# SAMA7G54D4G device description
Architecture: CORTEX-A7; Family: SAMA; Series: SAMA7G
Registers are 32-bit, read-write, reset 0x0 unless marked. A register's access mark holds for its fields unless they carry their own. Offsets are from the block's base; [hi:lo] are bit positions; {n}, {i} and the like mark numbered series; 'fields as' and 'values as' point back to an identical list.

## GPBR — General Purpose Backup Registers
Instances: GPBR 0xE001D060
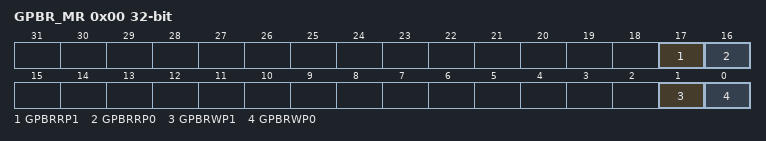
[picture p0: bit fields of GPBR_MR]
0x00 GPBR_MR — GPBR Mode Register
  [17] GPBRRP1 — GPBRx Read Protection
    0=The content of the corresponding GPBR register (32-bit part-select) can be read; 1=The corresponding GPBR register (32-bit part-select) always returns zero when read
  [16] GPBRRP0 — GPBRx Read Protection
    values as GPBRRP1
  [1] GPBRWP1 — GPBRx Write Protection
    0=The corresponding GPBR register (32-bit part-select) can be written; 1=The corresponding GPBR register (32-bit part-select) is write-protected
  [0] GPBRWP0 — GPBRx Write Protection
    values as GPBRWP1
0x04 GPBR_FCLR (atomic clear) — GPBR Full Clear Register
  [0] FCLR — Full Clear Enable
    0=SYS_GPBR0 to SYS_GPBR1 are immediately cleared in case of fast wakeup pin tamper event; 1=All SYS_GPBRx are immediately cleared in case of fast wakeup pin tamper event
{0x8+4i} SYS_GPBR[{i}] (i=0..1) — General Purpose Backup Register x
  [31:0] GPBR_VALUE — Value of SYS_GPBRx

## MCAN_RXBE — Rx Buffer Element
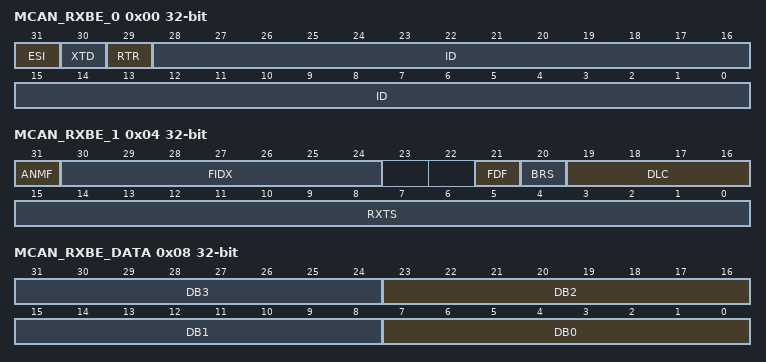
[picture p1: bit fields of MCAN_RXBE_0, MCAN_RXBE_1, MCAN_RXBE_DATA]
0x00 MCAN_RXBE_0 reset not defined — Rx Buffer Element 0
  [31] ESI — Error State Indicator
  [30] XTD — Extended Identifier
  [29] RTR — Remote Transmission Request
  [28:0] ID — Identifier
0x04 MCAN_RXBE_1 reset not defined — Rx Buffer Element 1
  [31] ANMF — Accepted Non-matching Frame
  [30:24] FIDX — Filter Index
  [21] FDF — FD Format
  [20] BRS — Bit Rate Switch
  [19:16] DLC — Data Length Code
  [15:0] RXTS — Rx Timestamp
0x08 MCAN_RXBE_DATA reset not defined — Rx Buffer Element Data
  [8n+7:8n] DB{n} (n=0..3) — Data Byte {n}

## MCAN_RXF0E — Rx FIFO 0 Element
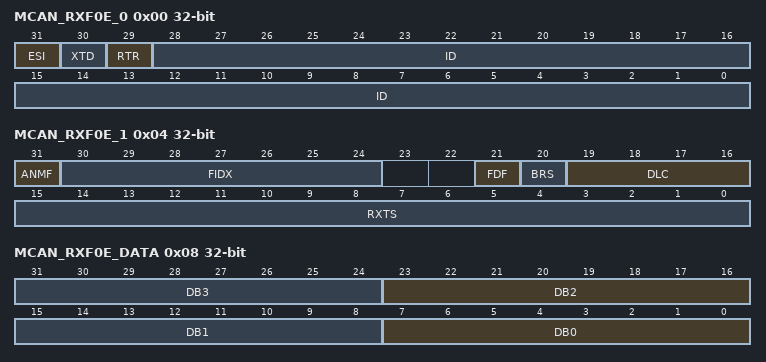
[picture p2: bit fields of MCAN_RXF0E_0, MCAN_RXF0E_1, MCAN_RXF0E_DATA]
0x00 MCAN_RXF0E_0 reset not defined — Rx FIFO 0 Element 0
  [31] ESI — Error State Indicator
  [30] XTD — Extended Identifier
  [29] RTR — Remote Transmission Request
  [28:0] ID — Identifier
0x04 MCAN_RXF0E_1 reset not defined — Rx FIFO 0 Element 1
  [31] ANMF — Accepted Non-matching Frame
  [30:24] FIDX — Filter Index
  [21] FDF — FD Format
  [20] BRS — Bit Rate Switch
  [19:16] DLC — Data Length Code
  [15:0] RXTS — Rx Timestamp
0x08 MCAN_RXF0E_DATA reset not defined — Rx FIFO 0 Element Data
  [8n+7:8n] DB{n} (n=0..3) — Data Byte {n}

## MCAN_RXF1E — Rx FIFO 1 Element
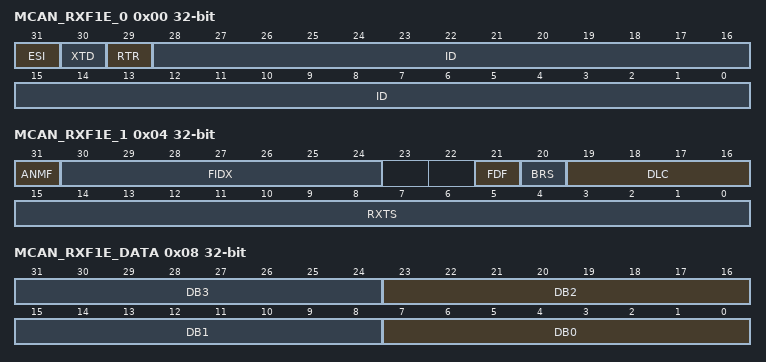
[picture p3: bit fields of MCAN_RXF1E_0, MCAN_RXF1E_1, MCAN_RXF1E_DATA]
0x00 MCAN_RXF1E_0 reset not defined — Rx FIFO 1 Element 0
  [31] ESI — Error State Indicator
  [30] XTD — Extended Identifier
  [29] RTR — Remote Transmission Request
  [28:0] ID — Identifier
0x04 MCAN_RXF1E_1 reset not defined — Rx FIFO 1 Element 1
  [31] ANMF — Accepted Non-matching Frame
  [30:24] FIDX — Filter Index
  [21] FDF — FD Format
  [20] BRS — Bit Rate Switch
  [19:16] DLC — Data Length Code
  [15:0] RXTS — Rx Timestamp
0x08 MCAN_RXF1E_DATA reset not defined — Rx FIFO 1 Element Data
  [8n+7:8n] DB{n} (n=0..3) — Data Byte {n}

## MCAN_TXBE — Tx Buffer Element
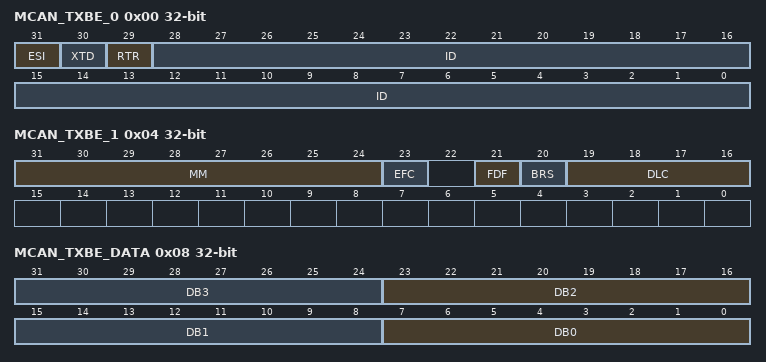
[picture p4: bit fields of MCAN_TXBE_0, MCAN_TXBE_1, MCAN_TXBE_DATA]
0x00 MCAN_TXBE_0 reset not defined — Tx Buffer Element 0
  [31] ESI — Error State Indicator
  [30] XTD — Extended Identifier
  [29] RTR — Remote Transmission Request
  [28:0] ID — Identifier
0x04 MCAN_TXBE_1 reset not defined — Tx Buffer Element 1
  [31:24] MM — Message Marker
  [23] EFC — Event FIFO Control
  [21] FDF — FD Format
  [20] BRS — Bit Rate Switch
  [19:16] DLC — Data Length Code
0x08 MCAN_TXBE_DATA reset not defined — Tx Buffer Element Data
  [8n+7:8n] DB{n} (n=0..3) — Data Byte {n}

## MCAN_TXEFE — Tx Event FIFO Element
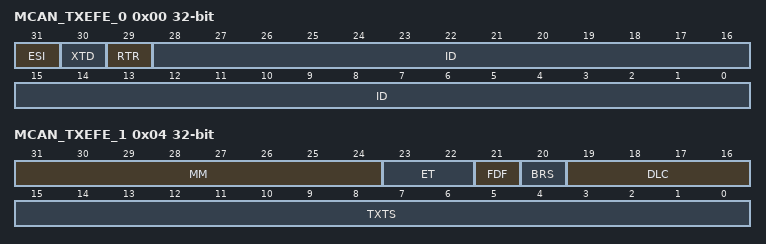
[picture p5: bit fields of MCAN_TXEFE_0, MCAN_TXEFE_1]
0x00 MCAN_TXEFE_0 reset not defined — Tx Event FIFO Element 0
  [31] ESI — Error State Indicator
  [30] XTD — Extended Identifier
  [29] RTR — Remote Transmission Request
  [28:0] ID — Identifier
0x04 MCAN_TXEFE_1 reset not defined — Tx Event FIFO Element 1
  [31:24] MM — Message Marker
  [23:22] ET — Event Type
    1=TXE (Tx event); 2=TXC (Transmission in spite of cancellation)
  [21] FDF — FD Format
  [20] BRS — Bit Rate Switch
  [19:16] DLC — Data Length Code
  [15:0] TXTS — Tx Timestamp

## Notices in the file
Copyright (c) 2020 Microchip Technology Inc.
SPDX-License-Identifier: Apache-2.0
Licensed under the Apache License, Version 2.0 (the "License");
you may not use this file except in compliance with the License.
You may obtain a copy of the License at
http://www.apache.org/licenses/LICENSE-2.0
Unless required by applicable law or agreed to in writing, software
distributed under the License is distributed on an "AS IS" BASIS,
WITHOUT WARRANTIES OR CONDITIONS OF ANY KIND, either express or implied.
See the License for the specific language governing permissions and
limitations under the License.
